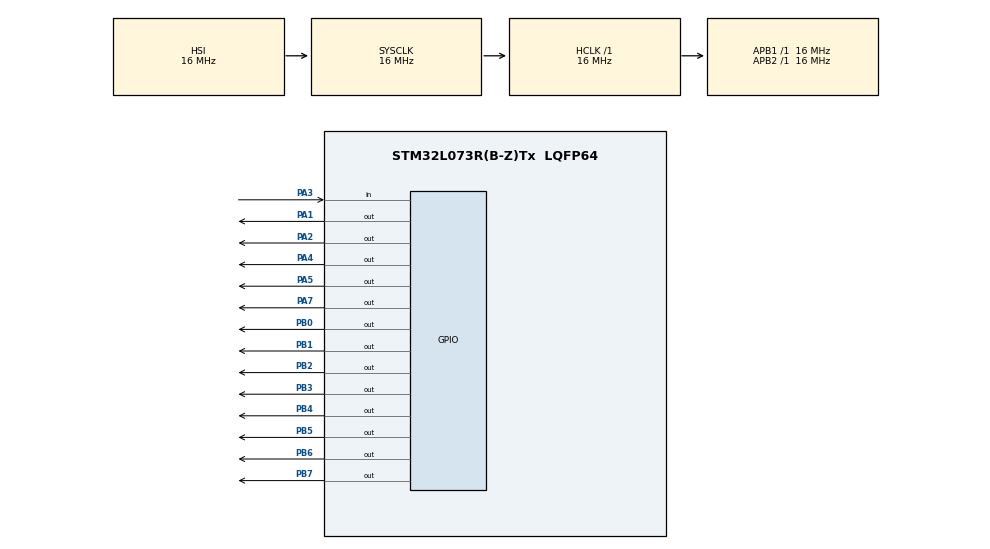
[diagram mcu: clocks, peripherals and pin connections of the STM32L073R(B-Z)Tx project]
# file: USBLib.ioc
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Mcu.Family=STM32L0
Mcu.Name=STM32L073R(B-Z)Tx
Mcu.Package=LQFP64
PA1.GPIO_Speed=GPIO_SPEED_FREQ_VERY_HIGH
PA1.Signal=GPIO_Output
PA2.GPIO_Speed=GPIO_SPEED_FREQ_VERY_HIGH
PA2.Signal=GPIO_Output
PA3.Signal=GPIO_Input
PA4.GPIO_Speed=GPIO_SPEED_FREQ_VERY_HIGH
PA4.Signal=GPIO_Output
PA5.GPIO_Speed=GPIO_SPEED_FREQ_VERY_HIGH
PA5.Signal=GPIO_Output
PA7.GPIO_Speed=GPIO_SPEED_FREQ_VERY_HIGH
PA7.Signal=GPIO_Output
PB0.Signal=GPIO_Output
PB1.Signal=GPIO_Output
PB2.Signal=GPIO_Output
PB3.Signal=GPIO_Output
PB4.Signal=GPIO_Output
PB5.Signal=GPIO_Output
PB6.Signal=GPIO_Output
PB7.Signal=GPIO_Output
ProjectManager.HeapSize=0x200
ProjectManager.StackSize=0x400
ProjectManager.TargetToolchain=Makefile
RCC.AHBFreq_Value=16000000
RCC.APB1Freq_Value=16000000
RCC.APB1TimFreq_Value=16000000
RCC.APB2Freq_Value=16000000
RCC.APB2TimFreq_Value=16000000
RCC.HCLKFreq_Value=16000000
RCC.HSE_VALUE=8000000
RCC.HSI16_VALUE=16000000
RCC.HSI48MClockSelection=RCC_USBCLKSOURCE_HSI48
RCC.HSI48_VALUE=48000000
RCC.HSI_VALUE=16000000
RCC.LSE_VALUE=32768
RCC.MSI_VALUE=2097000
RCC.PLLMUL=RCC_PLLMUL_4
RCC.SYSCLKFreq_VALUE=16000000
RCC.SYSCLKSource=RCC_SYSCLKSOURCE_HSI
RCC.VCOOutputFreq_Value=64000000
board=custom

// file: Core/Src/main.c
/* USER CODE BEGIN Header */
/**
  ******************************************************************************
  * @file           : main.c
  * @brief          : Main program body
  ******************************************************************************
  * @attention
  *
  * Copyright (c) 2022 STMicroelectronics.
  * All rights reserved.
  *
  * This software is licensed under terms that can be found in the LICENSE file
  * in the root directory of this software component.
  * If no LICENSE file comes with this software, it is provided AS-IS.
  *
  ******************************************************************************
  */
/* USER CODE END Header */
#include "main.h"

/* USER CODE BEGIN Includes */
//#include "EPD_1in54_V2.h"
//#include "GUI_Paint.h"
//#include "usbd_cdc_if.h"
/* USER CODE END Includes */

void SystemClock_Config(void);
static void MX_GPIO_Init(void);

/* USER CODE BEGIN 0 */
void db_LED_OFF(int i) {
    HAL_GPIO_WritePin(GPIOB, 1 << i, GPIO_PIN_RESET);
}
void db_LED_ON(int i) {
    HAL_GPIO_WritePin(GPIOB, 1 << i, GPIO_PIN_SET);
}

void db_LED(int i, int val){
    HAL_GPIO_WritePin(GPIOB, 1 << i, val);
}

/*
void db_PUT(const char* str) {
    uint16_t len = strlen(str);
    uint8_t* s = (uint8_t*) malloc(len);
    memcpy(s, str, len);
    CDC_Transmit_FS(s, len);
    free(s);
}
*/

void init_test();
void small_test();

/* USER CODE END 0 */

int main(void)
{

  /* MCU Configuration--------------------------------------------------------*/

  /* Reset of all peripherals, Initializes the Flash interface and the Systick. */
  HAL_Init();

  /* Configure the system clock */
  SystemClock_Config();

  /* Initialize all configured peripherals */
  MX_GPIO_Init();
  /* USER CODE BEGIN 2 */
  //SPI_test();
  init_test();
  //small_test();
  //test();
  /* USER CODE END 2 */

  /* Infinite loop */
  while (1)
  {

  }
}

void SystemClock_Config(void)
{
  RCC_OscInitTypeDef RCC_OscInitStruct = {0};
  RCC_ClkInitTypeDef RCC_ClkInitStruct = {0};

  /** Configure the main internal regulator output voltage
  */
  __HAL_PWR_VOLTAGESCALING_CONFIG(PWR_REGULATOR_VOLTAGE_SCALE1);

  /** Initializes the RCC Oscillators according to the specified parameters
  * in the RCC_OscInitTypeDef structure.
  */
  RCC_OscInitStruct.OscillatorType = RCC_OSCILLATORTYPE_HSI;
  RCC_OscInitStruct.HSIState = RCC_HSI_ON;
  RCC_OscInitStruct.HSICalibrationValue = RCC_HSICALIBRATION_DEFAULT;
  RCC_OscInitStruct.PLL.PLLState = RCC_PLL_NONE;
  if (HAL_RCC_OscConfig(&RCC_OscInitStruct) != HAL_OK)
  {
    Error_Handler();
  }

  /** Initializes the CPU, AHB and APB buses clocks
  */
  RCC_ClkInitStruct.ClockType = RCC_CLOCKTYPE_HCLK|RCC_CLOCKTYPE_SYSCLK
                              |RCC_CLOCKTYPE_PCLK1|RCC_CLOCKTYPE_PCLK2;
  RCC_ClkInitStruct.SYSCLKSource = RCC_SYSCLKSOURCE_HSI;
  RCC_ClkInitStruct.AHBCLKDivider = RCC_SYSCLK_DIV1;
  RCC_ClkInitStruct.APB1CLKDivider = RCC_HCLK_DIV1;
  RCC_ClkInitStruct.APB2CLKDivider = RCC_HCLK_DIV1;

  if (HAL_RCC_ClockConfig(&RCC_ClkInitStruct, FLASH_LATENCY_0) != HAL_OK)
  {
    Error_Handler();
  }
}

static void MX_GPIO_Init(void)
{
  GPIO_InitTypeDef GPIO_InitStruct = {0};

  /* GPIO Ports Clock Enable */
  __HAL_RCC_GPIOA_CLK_ENABLE();
  __HAL_RCC_GPIOB_CLK_ENABLE();

  /*Configure GPIO pin Output Level */
  HAL_GPIO_WritePin(GPIOA, GPIO_PIN_1|GPIO_PIN_2|GPIO_PIN_4|GPIO_PIN_5
                          |GPIO_PIN_7, GPIO_PIN_RESET);

  /*Configure GPIO pin Output Level */
  HAL_GPIO_WritePin(GPIOB, GPIO_PIN_0|GPIO_PIN_1|GPIO_PIN_2|GPIO_PIN_3
                          |GPIO_PIN_4|GPIO_PIN_5|GPIO_PIN_6|GPIO_PIN_7, GPIO_PIN_RESET);

  /*Configure GPIO pins : PA1 PA2 PA4 PA5
                           PA7 */
  GPIO_InitStruct.Pin = GPIO_PIN_1|GPIO_PIN_2|GPIO_PIN_4|GPIO_PIN_5
                          |GPIO_PIN_7;
  GPIO_InitStruct.Mode = GPIO_MODE_OUTPUT_PP;
  GPIO_InitStruct.Pull = GPIO_NOPULL;
  GPIO_InitStruct.Speed = GPIO_SPEED_FREQ_VERY_HIGH;
  HAL_GPIO_Init(GPIOA, &GPIO_InitStruct);

  /*Configure GPIO pin : PA3 */
  GPIO_InitStruct.Pin = GPIO_PIN_3;
  GPIO_InitStruct.Mode = GPIO_MODE_INPUT;
  GPIO_InitStruct.Pull = GPIO_NOPULL;
  HAL_GPIO_Init(GPIOA, &GPIO_InitStruct);

  /*Configure GPIO pins : PB0 PB1 PB2 PB3
                           PB4 PB5 PB6 PB7 */
  GPIO_InitStruct.Pin = GPIO_PIN_0|GPIO_PIN_1|GPIO_PIN_2|GPIO_PIN_3
                          |GPIO_PIN_4|GPIO_PIN_5|GPIO_PIN_6|GPIO_PIN_7;
  GPIO_InitStruct.Mode = GPIO_MODE_OUTPUT_PP;
  GPIO_InitStruct.Pull = GPIO_NOPULL;
  GPIO_InitStruct.Speed = GPIO_SPEED_FREQ_LOW;
  HAL_GPIO_Init(GPIOB, &GPIO_InitStruct);

}

void Error_Handler(void)
{
  __disable_irq();
  while (1)
  {
  }
}
